# WB32F10x register map
File version: 1.2
CPU: CM3 r2p0, little endian, MPU, no FPU, 4 interrupt priority bits
Registers are 32-bit, read-write, reset 0x0 unless marked. A register's access mark holds for its fields unless they carry their own. Offsets are from the block's base; [hi:lo] are bit positions.

## I2S — Inter-IC Sound Bus
Base 0x4000B400
0x00 RTCCR — RTC signal output control register
  [0] IEN — I2S Enable
0x04 IRER — I2S Receiver Block Enable Register
  [0] RXEN — Receiver block enable
0x08 ITER — I2S Transmitter Block Enable Register
  [0] TXEN — Transmitter block enable
0x0C CER — Clock Enable Register
  [0] CLKEN — Clock generation enable/disable
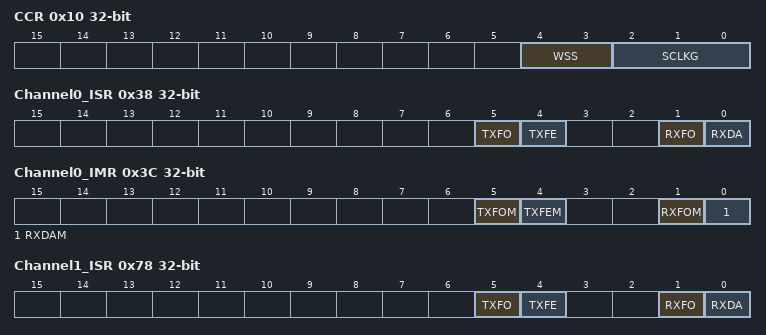
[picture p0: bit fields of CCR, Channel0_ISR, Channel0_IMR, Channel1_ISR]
0x10 CCR — Clock Configuration Register
  [4:3] WSS — Set the clock length for the left and right channels
  [2:0] SCLKG — These bits are used to program the gating of sclk
0x14 RXFFR wo — Receiver Block FIFO Reset Register
  [0] RXFFR — Write 1 to clear RX FIFO
0x18 TXFFR wo — Transmitter Block FIFO Reset Register
  [0] TXFFR — Write 1 to clear TX FIFO
0x20 Channel0_LRBR ro — Channel0 Left Receive Buffer Register
  [31:0] LRBR — The left channel of Channel0 receives buffer data
0x20 Channel0_LTHR wo (alternate view of Channel0_LRBR) — Channel0 Left Transmit Holding Register
  [31:0] LTHR — The left channel of Channel0 Transmit buffer data
0x24 Channel0_RRBR wo — Channel0 Right Receive Buffer Register
  [31:0] RRBR — The right channel of Channel0 receives buffer data
0x24 Channel0_RTHR wo (alternate view of Channel0_RRBR) — Channel0 Right Transmit Holding Register
  [31:0] RTHR — The right channel of Channel0 Transmit buffer data
0x28 Channel0_RER wo — Channel0 Receive Enable Register
  [0] RXCHEN — Channel0 receive enable
0x2C Channel0_TER wo — Channel0 Transmit Enable Register
  [0] TXCHEN — Channel0 Transmit enable
0x30 Channel0_RCR — Channel0 Receive Configuration Register
  [2:0] WLEN — Channel receive resolution
0x34 Channel0_TCR — Channel0 Transmit Configuration Register
  [2:0] WLEN — Channel transmit resolution
0x38 Channel0_ISR ro — Channel0 Interrupt Status Register
  [5] TXFO — Channel0 TX FIFO overrun
  [4] TXFE — Channel0 TX FIFO empty
  [1] RXFO — Channel0 RX FIFO overrun
  [0] RXDA — Channel0 RX FIFO not empty
0x3C Channel0_IMR — Channel0 Interrupt Mask Register
  [5] TXFOM — Channel0 mask TX FIFO overrun interrupt
  [4] TXFEM — Channel0 mask TX FIFO empty interrupt
  [1] RXFOM — Channel0 mask RX FIFO overrun interrupt
  [0] RXDAM — Channel0 mask RX FIFO not empty interrupt
0x40 Channel0_ROR ro — Channel0 Receive Overrun Register
  [0] RXCHO — Channel0 clear RX FIFO overrun interrupt
0x44 Channel0_TOR ro — Channel0 Transmit Overrun Register
  [0] CAL — Channel0 clear TX FIFO overrun interrupt
0x48 Channel0_RFCR — Channel0 RX FIFO Configuration Register
  [3:0] RXCHDT — Channel0 Config RX interrupt trigger level
0x4C Channel0_TFCR — Channel0 TX FIFO Configuration Register
  [3:0] TXCHET — Channel0 Config TX interrupt trigger level
0x50 Channel0_RFF wo — Channel0 RX FIFO Flush Register
  [0] RXCHFR — Write 1 to chear Channel0 RX FIFO
0x54 Channel0_TFF wo — Channel0 TX FIFO Flush Register
  [0] TXCHFR — Write 1 to chear Channel0 TX FIFO
0x60 Channel1_LRBR ro — Channel1 Left Receive Buffer Register
  [31:0] LRBR — The left channel of Channel1 receives buffer data
0x60 Channel1_LTHR wo (alternate view of Channel1_LRBR) — Channel1 Left Transmit Holding Register
  [31:0] LTHR — The left channel of Channel1 Transmit buffer data
0x64 Channel1_RRBR wo — Channel1 Right Receive Buffer Register
  [31:0] RRBR — The right channel of Channel1 receives buffer data
0x64 Channel1_RTHR wo (alternate view of Channel1_RRBR) — Channel1 Right Transmit Holding Register
  [31:0] RTHR — The right channel of Channel1 Transmit buffer data
0x68 Channel1_RER wo — Channel1 Receive Enable Register
  [0] RXCHEN — Channel1 receive enable
0x6C Channel1_TER wo — Channel1 Transmit Enable Register
  [0] TXCHEN — Channel1 Transmit enable
0x70 Channel1_RCR — Channel1 Receive Configuration Register
  [2:0] WLEN — Channel receive resolution
0x74 Channel1_TCR — Channel1 Transmit Configuration Register
  [2:0] WLEN — Channel transmit resolution
0x78 Channel1_ISR ro — Channel1 Interrupt Status Register
  [5] TXFO — Channel1 TX FIFO overrun
  [4] TXFE — Channel1 TX FIFO empty
  [1] RXFO — Channel1 RX FIFO overrun
  [0] RXDA — Channel1 RX FIFO not empty
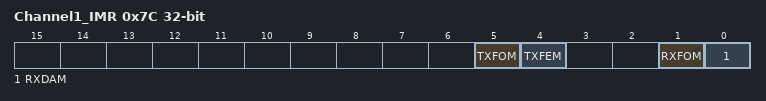
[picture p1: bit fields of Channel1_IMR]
0x7C Channel1_IMR — Channel1 Interrupt Mask Register
  [5] TXFOM — Channel1 mask TX FIFO overrun interrupt
  [4] TXFEM — Channel1 mask TX FIFO empty interrupt
  [1] RXFOM — Channel1 mask RX FIFO overrun interrupt
  [0] RXDAM — Channel1 mask RX FIFO not empty interrupt
0x80 Channel1_ROR ro — Channel1 Receive Overrun Register
  [0] RXCHO — Channel1 clear RX FIFO overrun interrupt
0x84 Channel1_TOR ro — Channel1 Transmit Overrun Register
  [0] CAL — Channel1 clear TX FIFO overrun interrupt
0x88 Channel1_RFCR — Channel1 RX FIFO Configuration Register
  [3:0] RXCHDT — Channel1 Config RX interrupt trigger level
0x8C Channel1_TFCR — Channel1 TX FIFO Configuration Register
  [3:0] TXCHET — Channel1 Config TX interrupt trigger level
0x90 Channel1_RFF wo — Channel1 RX FIFO Flush Register
  [0] RXCHFR — Write 1 to chear Channel1 RX FIFO
0x94 Channel1_TFF wo — Channel1 TX FIFO Flush Register
  [0] TXCHFR — Write 1 to chear Channel1 TX FIFO
0x1C0 RXDMA ro — Receiver Block DMA Register
0x1C4 RRXDMA wo — Reset Receiver Block DMA Register
0x1C8 TXDMA ro — Transmitter Block DMA Register
0x1CC RTXDMA wo — Reset Transmitter Block DMA Register
  [31:0] RRXDMA
